AUTOSAR XML (schema 4-2-2)
standard types defined: boolean, float32, sint16, uint8
package /ASW_COM_Pkg
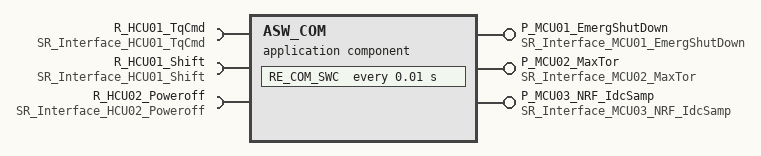
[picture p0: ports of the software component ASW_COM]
  application sw component type ASW_COM
    provide port P_MCU01_EmergShutDown: provided-interface=SR_Interface_MCU01_EmergShutDown
    provide port P_MCU02_MaxTor: provided-interface=SR_Interface_MCU02_MaxTor
    provide port P_MCU03_NRF_IdcSamp: provided-interface=SR_Interface_MCU03_NRF_IdcSamp
    require port R_HCU01_TqCmd: required-interface=SR_Interface_HCU01_TqCmd
    require port R_HCU01_Shift: required-interface=SR_Interface_HCU01_Shift
    require port R_HCU02_Poweroff: nonqueued-receiver-com-spec{data-element=DE_Poweroff, alive-timeout=0.3, init-value=0}, required-interface=SR_Interface_HCU02_Poweroff
    behavior IB_ASW_COM
      timing event TE_10ms_RE_COM_SWC: start-on-event=RE_COM_SWC, period=0.01
      runnable RE_COM_SWC
        data-read-access:
          access VA_Read_HCU01_TqCmd: accessed-variable=R_HCU01_TqCmd.DE_TqCmd
          access VA_Read_HCU01_Shift: accessed-variable=R_HCU01_Shift.DE_Shift
          access VA_Read_HCU02_Poweroff: accessed-variable=R_HCU02_Poweroff.DE_Poweroff
        data-write-access:
          access VA_Write_MCU01_EmergShutDown: accessed-variable=P_MCU01_EmergShutDown.DE_EmergShutDown
          access VA_Write_MCU02_MaxTor: accessed-variable=P_MCU02_MaxTor.DE_MaxTor
          access VA_Write_MCU03_NRF_IdcSamp: accessed-variable=P_MCU03_NRF_IdcSamp.DE_NRF_IdcSamp
package /COM_Interface
  6 x sender receiver interface:
    SR_Interface_HCU01_Shift
      data DE_Shift: type=Idt_UInt8
    SR_Interface_HCU01_TqCmd
      data DE_TqCmd: type=Idt_SInt16
    SR_Interface_HCU02_Poweroff
      data DE_Poweroff: type=Idt_Boolean
    SR_Interface_MCU01_EmergShutDown
      data DE_EmergShutDown: type=Idt_Boolean
    SR_Interface_MCU02_MaxTor
      data DE_MaxTor: type=Idt_SInt16
    SR_Interface_MCU03_NRF_IdcSamp
      data DE_NRF_IdcSamp: type=Idt_Float32
package /DataTypes
  4 x impl type, all with category=VALUE:
    Idt_Boolean: base-type=boolean
    Idt_Float32: base-type=float32
    Idt_SInt16: base-type=sint16
    Idt_UInt8: base-type=uint8
